# f29h85x_hsm_ecc_aggr_regs register map
Vendor: Texas Instruments
Peripheral module from a debugger description file (folder HSM).
Registers are 32-bit, read-write, no defined reset value unless marked. A register's access mark holds for its fields unless they carry their own. Offsets are as the file gives them; lines under a group give offsets from that group; [hi:lo] are bit positions; {n}, {i} and the like mark numbered series; 'fields as' and 'values as' point back to an identical list; <NAME> marks a mode.

## HSM_ECC_AGGR — HSM ECC AGGR Registers
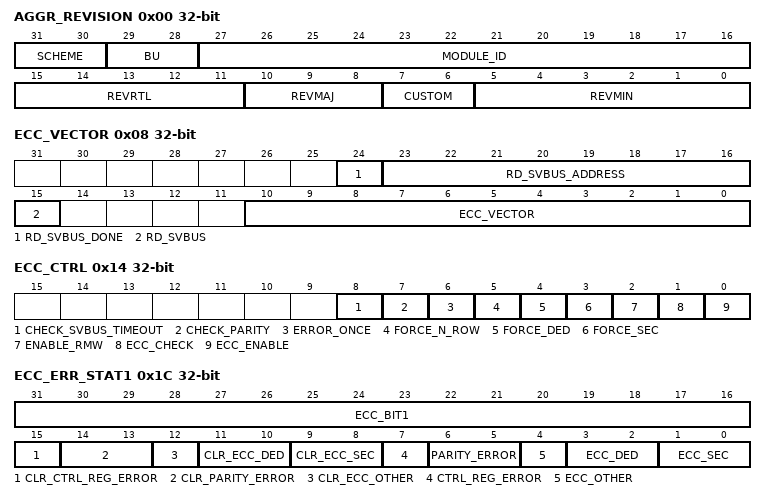
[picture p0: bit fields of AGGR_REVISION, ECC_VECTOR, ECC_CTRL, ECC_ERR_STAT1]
0x00 AGGR_REVISION ro — Aggregator Revision Register
  [31:30] SCHEME, [29:28] BU, [27:16] MODULE_ID, [15:11] REVRTL, [10:8] REVMAJ, [7:6] CUSTOM, [5:0] REVMIN
0x08 ECC_VECTOR
  [24] RD_SVBUS_DONE, [23:16] RD_SVBUS_ADDRESS, [15] RD_SVBUS, [10:0] ECC_VECTOR
0x0C MISC_STATUS ro
  [10:0] NUM_RAMS
0x14 ECC_CTRL — ECC Control Register
  [8] CHECK_SVBUS_TIMEOUT, [7] CHECK_PARITY, [6] ERROR_ONCE, [5] FORCE_N_ROW, [4] FORCE_DED, [3] FORCE_SEC, [2] ENABLE_RMW, [1] ECC_CHECK, [0] ECC_ENABLE
0x18 ECC_ERR_CTRL1 — ECC Error Control1 Register
  [31:0] ECC_ROW
0x1C ECC_ERR_STAT1 access per field — ECC Error Status1 Register
  [31:16] ECC_BIT1 ro, [15] CLR_CTRL_REG_ERROR rw, [14:13] CLR_PARITY_ERROR rw, [12] CLR_ECC_OTHER rw, [11:10] CLR_ECC_DED rw, [9:8] CLR_ECC_SEC rw, [7] CTRL_REG_ERROR rw, [6:5] PARITY_ERROR rw, [4] ECC_OTHER rw, [3:2] ECC_DED rw, [1:0] ECC_SEC rw
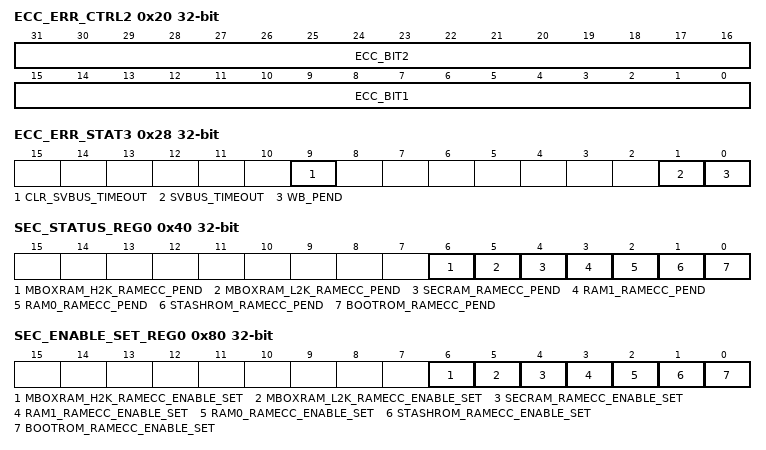
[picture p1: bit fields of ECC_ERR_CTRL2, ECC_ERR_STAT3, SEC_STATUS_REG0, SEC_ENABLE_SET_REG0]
0x20 ECC_ERR_CTRL2 — ECC Error Control2 Register
  [31:16] ECC_BIT2, [15:0] ECC_BIT1
0x24 ECC_ERR_STAT2 ro — ECC Error Status2 Register
  [31:0] ECC_ROW
0x28 ECC_ERR_STAT3 access per field — ECC Error Status3 Register
  [9] CLR_SVBUS_TIMEOUT rw, [1] SVBUS_TIMEOUT rw, [0] WB_PEND ro
0x3C SEC_EOI_REG — EOI Register
  [0] EOI_WR
0x40 SEC_STATUS_REG0 — Interrupt Status Register 0
  [6] MBOXRAM_H2K_RAMECC_PEND, [5] MBOXRAM_L2K_RAMECC_PEND, [4] SECRAM_RAMECC_PEND, [3] RAM1_RAMECC_PEND, [2] RAM0_RAMECC_PEND, [1] STASHROM_RAMECC_PEND, [0] BOOTROM_RAMECC_PEND
0x80 SEC_ENABLE_SET_REG0 — Interrupt Enable Set Register 0
  [6] MBOXRAM_H2K_RAMECC_ENABLE_SET, [5] MBOXRAM_L2K_RAMECC_ENABLE_SET, [4] SECRAM_RAMECC_ENABLE_SET, [3] RAM1_RAMECC_ENABLE_SET, [2] RAM0_RAMECC_ENABLE_SET, [1] STASHROM_RAMECC_ENABLE_SET, [0] BOOTROM_RAMECC_ENABLE_SET
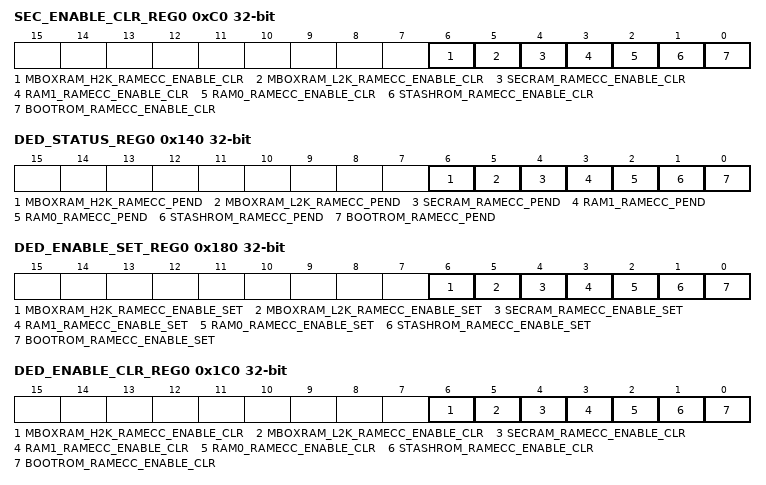
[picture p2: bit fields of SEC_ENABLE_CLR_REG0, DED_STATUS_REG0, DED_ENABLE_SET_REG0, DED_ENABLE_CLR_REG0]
0xC0 SEC_ENABLE_CLR_REG0 — Interrupt Enable Clear Register 0
  [6] MBOXRAM_H2K_RAMECC_ENABLE_CLR, [5] MBOXRAM_L2K_RAMECC_ENABLE_CLR, [4] SECRAM_RAMECC_ENABLE_CLR, [3] RAM1_RAMECC_ENABLE_CLR, [2] RAM0_RAMECC_ENABLE_CLR, [1] STASHROM_RAMECC_ENABLE_CLR, [0] BOOTROM_RAMECC_ENABLE_CLR
0x13C DED_EOI_REG — EOI Register
  [0] EOI_WR
0x140 DED_STATUS_REG0 — Interrupt Status Register 0
  fields as SEC_STATUS_REG0
0x180 DED_ENABLE_SET_REG0 — Interrupt Enable Set Register 0
  fields as SEC_ENABLE_SET_REG0
0x1C0 DED_ENABLE_CLR_REG0 — Interrupt Enable Clear Register 0
  fields as SEC_ENABLE_CLR_REG0
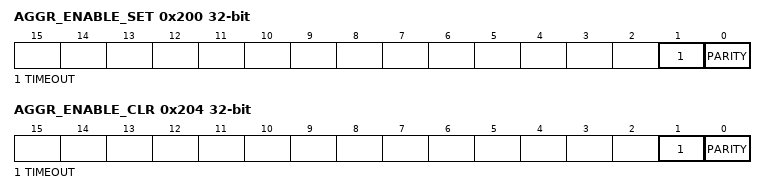
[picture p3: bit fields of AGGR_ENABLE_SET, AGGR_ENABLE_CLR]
0x200 AGGR_ENABLE_SET — AGGR interrupt enable set Register
  [1] TIMEOUT, [0] PARITY
0x204 AGGR_ENABLE_CLR — AGGR interrupt enable clear Register
  [1] TIMEOUT, [0] PARITY
0x208 AGGR_STATUS_SET access not given — AGGR interrupt status set Register
0x20C AGGR_STATUS_CLR access not given — AGGR interrupt status clear Register
